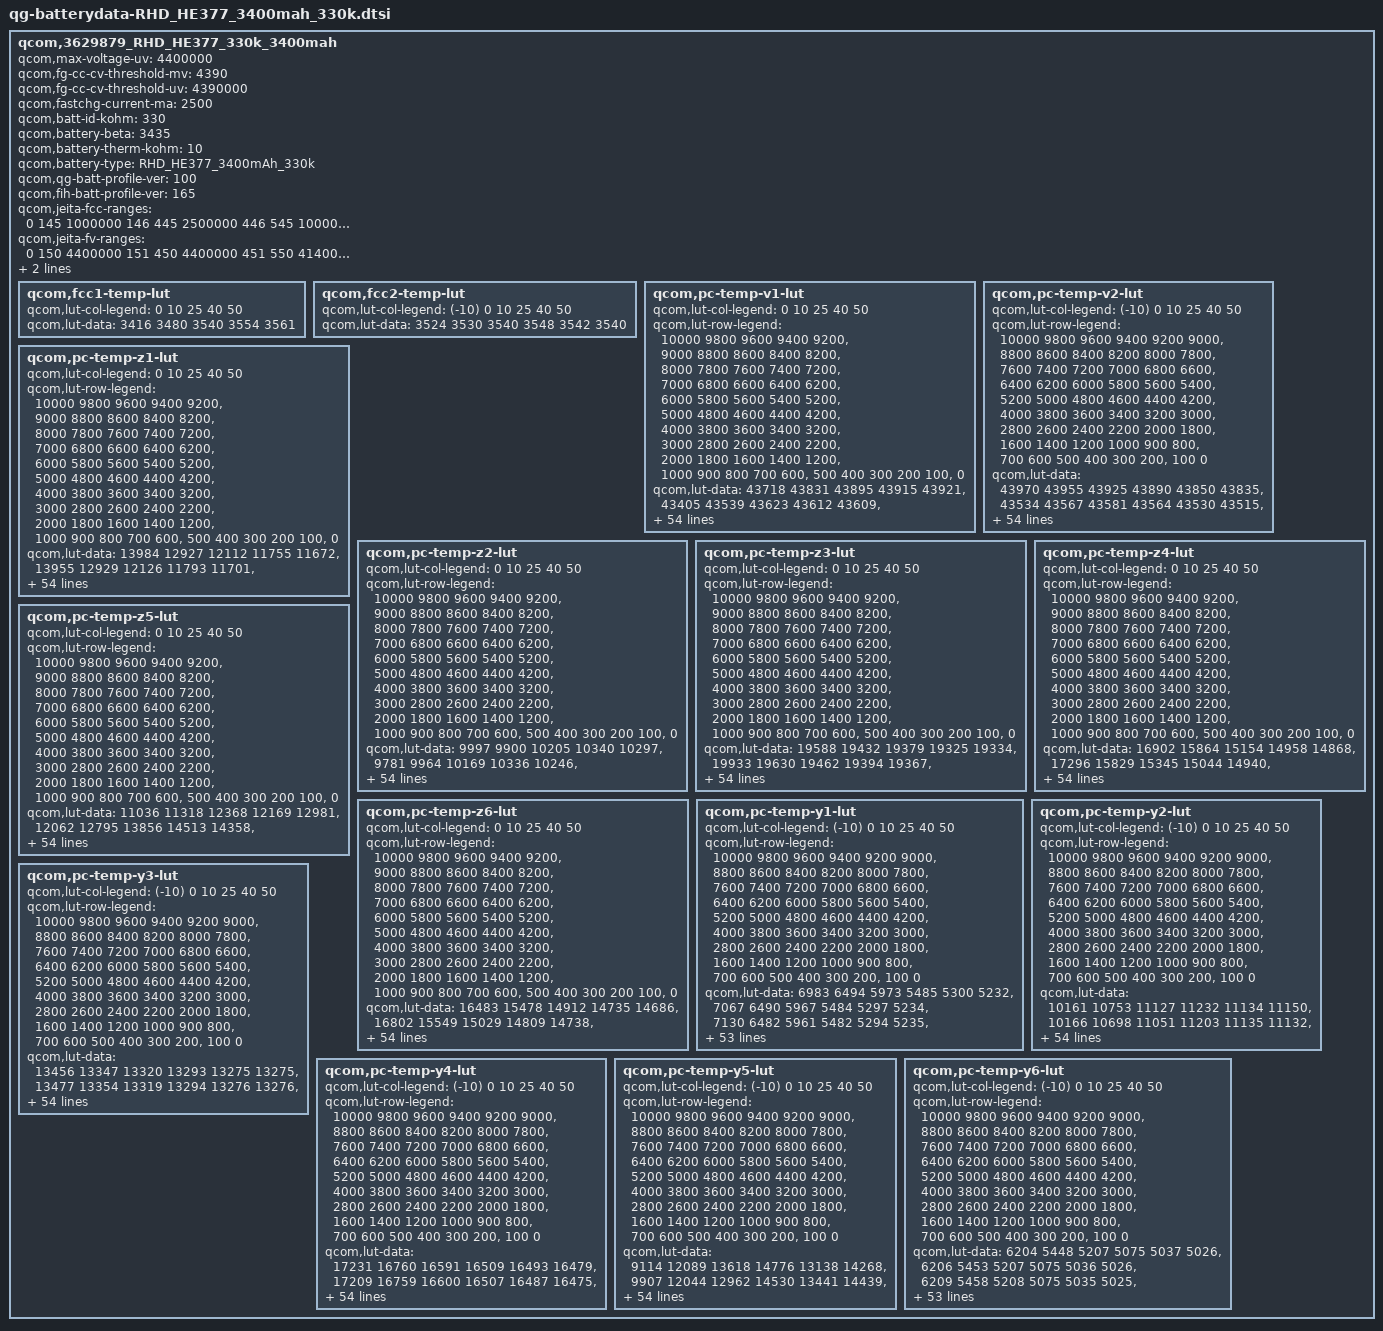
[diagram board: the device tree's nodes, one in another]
qcom,3629879_RHD_HE377_330k_3400mah {
	/* 3629879_FIH_HE377_3500mAh_averaged_MasterSlave_Oct1st2018 */
	qcom,max-voltage-uv = <4400000>;
	qcom,fg-cc-cv-threshold-mv = <4390>; // not use
	qcom,fg-cc-cv-threshold-uv = <4390000>; // not use
	qcom,fastchg-current-ma = <2500>;
	qcom,batt-id-kohm = <330>;
	qcom,battery-beta = <3435>;
	qcom,battery-therm-kohm = <10>;
	qcom,battery-type =
		"RHD_HE377_3400mAh_330k";
	qcom,qg-batt-profile-ver = <100>;
	qcom,fih-batt-profile-ver = <165>;

	qcom,jeita-fcc-ranges = <0   145   1000000
				 146 445  2500000
				 446 545  1000000
				 546 550  100000>;
	qcom,jeita-fv-ranges =  <0   150  4400000
				 151 450  4400000
				 451 550  4140000>;

	qcom,jeita-soft-thresholds = <0x257d 0xfb3>;
	qcom,jeita-hard-thresholds = <0x3733 0xbc2>;

	qcom,fcc1-temp-lut {
		qcom,lut-col-legend = <0 10 25 40 50>;
		qcom,lut-data = <3416 3480 3540 3554 3561>;
	};

	qcom,fcc2-temp-lut {
		qcom,lut-col-legend = <(-10) 0 10 25 40 50>;
		qcom,lut-data = <3524 3530 3540 3548 3542 3540>;
	};

	qcom,pc-temp-v1-lut {
		qcom,lut-col-legend = <0 10 25 40 50>;
		qcom,lut-row-legend = <10000 9800 9600 9400 9200>,
			<9000 8800 8600 8400 8200>,
			<8000 7800 7600 7400 7200>,
			<7000 6800 6600 6400 6200>,
			<6000 5800 5600 5400 5200>,
			<5000 4800 4600 4400 4200>,
			<4000 3800 3600 3400 3200>,
			<3000 2800 2600 2400 2200>,
			<2000 1800 1600 1400 1200>,
			<1000 900 800 700 600>,
			<500 400 300 200 100>,
			<0>;
		qcom,lut-data = <43718 43831 43895 43915 43921>,
			<43405 43539 43623 43612 43609>,
			<43133 43265 43357 43352 43348>,
			<42888 43011 43100 43108 43104>,
			<42653 42772 42854 42866 42865>,
			<42424 42539 42617 42630 42633>,
			<42202 42309 42382 42396 42403>,
			<41985 42084 42149 42163 42170>,
			<41773 41866 41921 41934 41940>,
			<41569 41653 41698 41708 41714>,
			<41387 41451 41481 41486 41491>,
			<41210 41270 41279 41269 41273>,
			<41001 41085 41095 41057 41056>,
			<40741 40857 40894 40848 40847>,
			<40474 40590 40639 40627 40643>,
			<40222 40338 40374 40408 40446>,
			<39980 40100 40169 40219 40257>,
			<39811 39895 40001 40055 40076>,
			<39706 39766 39849 39898 39903>,
			<39614 39677 39716 39747 39747>,
			<39504 39573 39586 39595 39596>,
			<39387 39434 39429 39414 39417>,
			<39262 39274 39250 39194 39197>,
			<39129 39083 39061 38991 38992>,
			<38993 38852 38842 38820 38825>,
			<38864 38673 38646 38670 38679>,
			<38737 38555 38535 38552 38556>,
			<38623 38464 38459 38453 38451>,
			<38522 38395 38386 38363 38356>,
			<38432 38340 38311 38278 38266>,
			<38365 38291 38243 38202 38186>,
			<38313 38243 38182 38134 38113>,
			<38269 38200 38129 38074 38048>,
			<38234 38162 38082 38020 37990>,
			<38205 38130 38043 37976 37940>,
			<38176 38098 38007 37934 37892>,
			<38152 38072 37971 37887 37838>,
			<38123 38043 37934 37837 37781>,
			<38079 37998 37885 37777 37715>,
			<38014 37926 37810 37704 37637>,
			<37933 37837 37718 37618 37547>,
			<37817 37728 37613 37511 37442>,
			<37681 37598 37487 37383 37318>,
			<37525 37440 37331 37227 37163>,
			<37373 37285 37181 37080 37015>,
			<37255 37171 37074 36980 36917>,
			<37218 37147 37044 36953 36892>,
			<37189 37121 37029 36936 36874>,
			<37164 37100 37012 36919 36859>,
			<37136 37075 36985 36889 36825>,
			<37029 36954 36830 36712 36623>,
			<36637 36558 36427 36307 36208>,
			<36082 36002 35870 35753 35647>,
			<35327 35242 35106 34993 34879>,
			<34141 34059 33921 33826 33685>,
			<30000 30000 30000 30000 30000>;
	};

	qcom,pc-temp-v2-lut {
		qcom,lut-col-legend = <(-10) 0 10 25 40 50>;
		qcom,lut-row-legend = <10000 9800 9600 9400 9200 9000>,
			<8800 8600 8400 8200 8000 7800>,
			<7600 7400 7200 7000 6800 6600>,
			<6400 6200 6000 5800 5600 5400>,
			<5200 5000 4800 4600 4400 4200>,
			<4000 3800 3600 3400 3200 3000>,
			<2800 2600 2400 2200 2000 1800>,
			<1600 1400 1200 1000 900 800>,
			<700 600 500 400 300 200>,
			<100 0>;
		qcom,lut-data = <43970 43955 43925 43890 43850 43835>,
			<43534 43567 43581 43564 43530 43515>,
			<43155 43222 43269 43264 43235 43219>,
			<42841 42928 42993 42994 42968 42953>,
			<42580 42678 42748 42751 42727 42714>,
			<42336 42440 42512 42515 42492 42481>,
			<42103 42207 42279 42280 42258 42247>,
			<41875 41981 42051 42048 42027 42016>,
			<41620 41760 41827 41821 41799 41788>,
			<41331 41541 41608 41597 41573 41562>,
			<41114 41336 41392 41376 41351 41340>,
			<41008 41159 41180 41154 41133 41122>,
			<40912 40982 40972 40937 40919 40908>,
			<40671 40765 40772 40741 40719 40703>,
			<40173 40508 40578 40558 40527 40503>,
			<39774 40231 40360 40355 40334 40310>,
			<39556 39905 40073 40095 40133 40121>,
			<39384 39602 39793 39853 39940 39939>,
			<39224 39423 39610 39704 39771 39771>,
			<39081 39302 39473 39596 39619 39614>,
			<38936 39170 39318 39453 39451 39443>,
			<38776 39007 39124 39230 39253 39249>,
			<38621 38842 38931 38999 39051 39051>,
			<38487 38698 38773 38815 38855 38855>,
			<38365 38565 38632 38652 38663 38662>,
			<38263 38446 38507 38517 38514 38512>,
			<38178 38340 38396 38406 38401 38398>,
			<38107 38242 38295 38307 38304 38300>,
			<38047 38148 38204 38216 38213 38207>,
			<37995 38058 38119 38133 38130 38120>,
			<37948 37985 38043 38057 38055 38043>,
			<37904 37923 37971 37986 37984 37973>,
			<37861 37872 37908 37920 37920 37909>,
			<37815 37831 37852 37858 37864 37853>,
			<37768 37798 37804 37801 37811 37800>,
			<37718 37762 37759 37745 37742 37725>,
			<37663 37725 37719 37691 37650 37610>,
			<37604 37683 37676 37633 37556 37495>,
			<37536 37632 37625 37565 37474 37406>,
			<37463 37571 37566 37490 37395 37326>,
			<37386 37498 37492 37410 37315 37243>,
			<37304 37407 37397 37320 37232 37160>,
			<37221 37291 37284 37211 37129 37056>,
			<37138 37143 37150 37076 36998 36924>,
			<37052 37030 37001 36927 36846 36782>,
			<36948 36941 36932 36885 36807 36749>,
			<36890 36902 36909 36871 36797 36737>,
			<36821 36859 36893 36852 36782 36724>,
			<36739 36807 36860 36825 36754 36693>,
			<36633 36714 36802 36745 36686 36614>,
			<36460 36534 36606 36487 36437 36324>,
			<36120 36148 36139 35982 35960 35829>,
			<35575 35548 35493 35320 35320 35174>,
			<34736 34690 34571 34372 34424 34254>,
			<33293 33297 33226 33050 33070 32859>,
			<28690 29213 28805 28338 29177 28649>;
	};

	qcom,pc-temp-z1-lut {
		qcom,lut-col-legend = <0 10 25 40 50>;
		qcom,lut-row-legend = <10000 9800 9600 9400 9200>,
			<9000 8800 8600 8400 8200>,
			<8000 7800 7600 7400 7200>,
			<7000 6800 6600 6400 6200>,
			<6000 5800 5600 5400 5200>,
			<5000 4800 4600 4400 4200>,
			<4000 3800 3600 3400 3200>,
			<3000 2800 2600 2400 2200>,
			<2000 1800 1600 1400 1200>,
			<1000 900 800 700 600>,
			<500 400 300 200 100>,
			<0>;
		qcom,lut-data = <13984 12927 12112 11755 11672>,
			<13955 12929 12126 11793 11701>,
			<13960 12928 12120 11790 11699>,
			<13967 12922 12114 11786 11697>,
			<13970 12913 12109 11783 11696>,
			<13963 12908 12103 11781 11695>,
			<13951 12910 12099 11779 11695>,
			<13941 12912 12095 11777 11694>,
			<13922 12907 12093 11776 11693>,
			<13908 12894 12092 11775 11692>,
			<13913 12888 12092 11774 11692>,
			<13924 12887 12092 11774 11691>,
			<13920 12888 12095 11778 11691>,
			<13879 12887 12096 11780 11691>,
			<13835 12885 12085 11775 11691>,
			<13803 12880 12069 11765 11690>,
			<13769 12857 12067 11763 11689>,
			<13759 12833 12069 11767 11691>,
			<13773 12835 12072 11771 11692>,
			<13787 12850 12078 11773 11693>,
			<13790 12864 12086 11775 11694>,
			<13796 12874 12091 11776 11695>,
			<13803 12883 12095 11777 11696>,
			<13813 12888 12098 11779 11698>,
			<13823 12891 12103 11782 11700>,
			<13834 12896 12109 11786 11703>,
			<13846 12909 12115 11790 11706>,
			<13853 12923 12121 11793 11709>,
			<13853 12926 12127 11797 11712>,
			<13851 12926 12132 11800 11715>,
			<13852 12927 12137 11804 11717>,
			<13855 12941 12142 11807 11720>,
			<13859 12959 12146 11811 11722>,
			<13872 12964 12151 11814 11724>,
			<13894 12964 12156 11817 11726>,
			<13908 12966 12161 11819 11729>,
			<13925 12971 12167 11822 11731>,
			<13939 12978 12173 11826 11733>,
			<13936 12986 12178 11829 11735>,
			<13923 12997 12183 11832 11737>,
			<13917 13005 12188 11836 11739>,
			<13915 13007 12192 11838 11742>,
			<13913 13011 12197 11840 11744>,
			<13911 13028 12202 11843 11746>,
			<13910 13040 12207 11846 11747>,
			<13912 13018 12208 11847 11748>,
			<13904 13015 12211 11848 11749>,
			<13889 13016 12208 11848 11749>,
			<13927 13023 12210 11851 11750>,
			<13931 13023 12212 11852 11753>,
			<13897 13027 12220 11857 11756>,
			<13930 13040 12231 11864 11763>,
			<13917 13065 12251 11875 11770>,
			<13938 13117 12269 11889 11783>,
			<13938 13117 12269 11889 11783>,
			<13938 13117 12269 11889 11783>;
	};

	qcom,pc-temp-z2-lut {
		qcom,lut-col-legend = <0 10 25 40 50>;
		qcom,lut-row-legend = <10000 9800 9600 9400 9200>,
			<9000 8800 8600 8400 8200>,
			<8000 7800 7600 7400 7200>,
			<7000 6800 6600 6400 6200>,
			<6000 5800 5600 5400 5200>,
			<5000 4800 4600 4400 4200>,
			<4000 3800 3600 3400 3200>,
			<3000 2800 2600 2400 2200>,
			<2000 1800 1600 1400 1200>,
			<1000 900 800 700 600>,
			<500 400 300 200 100>,
			<0>;
		qcom,lut-data = <9997 9900 10205 10340 10297>,
			<9781 9964 10169 10336 10246>,
			<9791 9999 10241 10402 10360>,
			<9834 9994 10294 10459 10483>,
			<9853 9974 10277 10448 10480>,
			<9851 9960 10244 10411 10420>,
			<9847 9952 10238 10398 10390>,
			<9840 9947 10246 10414 10394>,
			<9830 9941 10257 10429 10398>,
			<9819 9935 10267 10427 10380>,
			<9810 9933 10279 10421 10344>,
			<9802 9942 10288 10422 10333>,
			<9792 9957 10300 10434 10298>,
			<9774 9973 10308 10444 10263>,
			<9763 9993 10315 10445 10277>,
			<9768 10011 10320 10444 10310>,
			<9784 10026 10322 10430 10332>,
			<9797 10041 10325 10359 10342>,
			<9810 10070 10330 10311 10353>,
			<9820 10115 10361 10326 10372>,
			<9821 10143 10397 10366 10403>,
			<9819 10152 10400 10444 10477>,
			<9820 10159 10398 10630 10684>,
			<9828 10170 10394 10733 10814>,
			<9840 10185 10370 10586 10713>,
			<9856 10190 10345 10383 10542>,
			<9878 10187 10353 10383 10483>,
			<9898 10181 10384 10497 10464>,
			<9914 10175 10396 10553 10446>,
			<9928 10169 10389 10507 10388>,
			<9941 10166 10378 10445 10317>,
			<9953 10170 10365 10422 10284>,
			<9964 10176 10350 10407 10260>,
			<9974 10183 10346 10400 10252>,
			<9984 10193 10352 10400 10287>,
			<9997 10204 10363 10405 10343>,
			<10017 10217 10378 10449 10392>,
			<10040 10232 10399 10546 10440>,
			<10068 10242 10420 10576 10477>,
			<10100 10249 10444 10544 10504>,
			<10129 10256 10460 10514 10525>,
			<10154 10263 10460 10545 10541>,
			<10171 10270 10458 10595 10552>,
			<10142 10289 10471 10565 10536>,
			<10044 10420 10509 10544 10528>,
			<9993 10507 10540 10526 10506>,
			<9989 10746 10525 10556 10537>,
			<9963 10850 10533 10563 10547>,
			<9916 10934 10559 10547 10565>,
			<9938 11040 10576 10577 10705>,
			<9672 11013 10655 10634 10519>,
			<9723 10748 10712 10500 10298>,
			<9727 10567 10722 10447 10225>,
			<9587 10375 10643 10344 10140>,
			<9587 10375 10643 10344 10140>,
			<9587 10375 10643 10344 10140>;
	};

	qcom,pc-temp-z3-lut {
		qcom,lut-col-legend = <0 10 25 40 50>;
		qcom,lut-row-legend = <10000 9800 9600 9400 9200>,
			<9000 8800 8600 8400 8200>,
			<8000 7800 7600 7400 7200>,
			<7000 6800 6600 6400 6200>,
			<6000 5800 5600 5400 5200>,
			<5000 4800 4600 4400 4200>,
			<4000 3800 3600 3400 3200>,
			<3000 2800 2600 2400 2200>,
			<2000 1800 1600 1400 1200>,
			<1000 900 800 700 600>,
			<500 400 300 200 100>,
			<0>;
		qcom,lut-data = <19588 19432 19379 19325 19334>,
			<19933 19630 19462 19394 19367>,
			<19991 19751 19515 19427 19403>,
			<20000 19766 19538 19446 19427>,
			<20003 19770 19538 19453 19431>,
			<19988 19771 19535 19458 19432>,
			<19967 19765 19532 19458 19432>,
			<19964 19758 19526 19450 19428>,
			<19966 19751 19517 19440 19420>,
			<19968 19737 19504 19428 19411>,
			<19962 19722 19491 19415 19401>,
			<19951 19700 19486 19410 19394>,
			<19948 19681 19483 19408 19388>,
			<19955 19676 19482 19407 19382>,
			<19960 19673 19482 19406 19374>,
			<19944 19669 19482 19405 19365>,
			<19899 19657 19479 19401 19360>,
			<19852 19638 19465 19382 19357>,
			<19792 19613 19453 19366 19353>,
			<19748 19581 19444 19362 19346>,
			<19750 19568 19438 19360 19337>,
			<19768 19580 19443 19365 19339>,
			<19791 19600 19460 19393 19363>,
			<19831 19625 19468 19409 19380>,
			<19873 19657 19467 19387 19362>,
			<19891 19671 19464 19357 19333>,
			<19901 19669 19458 19357 19335>,
			<19905 19664 19448 19375 19366>,
			<19904 19658 19445 19391 19386>,
			<19899 19648 19459 19400 19388>,
			<19893 19640 19474 19407 19387>,
			<19880 19636 19477 19406 19384>,
			<19865 19632 19478 19402 19378>,
			<19849 19628 19477 19396 19371>,
			<19830 19623 19472 19389 19365>,
			<19809 19617 19467 19383 19359>,
			<19785 19612 19463 19381 19355>,
			<19761 19606 19460 19380 19351>,
			<19742 19601 19457 19377 19350>,
			<19725 19597 19453 19371 19349>,
			<19707 19592 19448 19366 19349>,
			<19687 19581 19442 19366 19346>,
			<19659 19569 19435 19367 19342>,
			<19553 19557 19432 19366 19345>,
			<19401 19515 19423 19361 19346>,
			<19344 19491 19413 19355 19345>,
			<19336 19349 19411 19349 19337>,
			<19330 19337 19387 19345 19332>,
			<19327 19323 19371 19344 19326>,
			<19317 19317 19376 19338 19312>,
			<19274 19325 19363 19341 19338>,
			<19307 19329 19356 19354 19356>,
			<19345 19329 19348 19352 19357>,
			<19356 19322 19349 19360 19362>,
			<19356 19322 19349 19360 19362>,
			<19356 19322 19349 19360 19362>;
	};

	qcom,pc-temp-z4-lut {
		qcom,lut-col-legend = <0 10 25 40 50>;
		qcom,lut-row-legend = <10000 9800 9600 9400 9200>,
			<9000 8800 8600 8400 8200>,
			<8000 7800 7600 7400 7200>,
			<7000 6800 6600 6400 6200>,
			<6000 5800 5600 5400 5200>,
			<5000 4800 4600 4400 4200>,
			<4000 3800 3600 3400 3200>,
			<3000 2800 2600 2400 2200>,
			<2000 1800 1600 1400 1200>,
			<1000 900 800 700 600>,
			<500 400 300 200 100>,
			<0>;
		qcom,lut-data = <16902 15864 15154 14958 14868>,
			<17296 15829 15345 15044 14940>,
			<17234 15755 15232 15004 14920>,
			<16820 15624 15107 14945 14886>,
			<16431 15414 15032 14900 14854>,
			<16181 15259 14971 14859 14821>,
			<15970 15163 14919 14830 14796>,
			<15804 15091 14871 14806 14780>,
			<15669 15039 14843 14790 14768>,
			<15558 15000 14835 14784 14762>,
			<15462 14967 14829 14780 14758>,
			<15381 14932 14821 14775 14754>,
			<15332 14908 14809 14770 14749>,
			<15302 14904 14800 14763 14742>,
			<15275 14902 14796 14755 14737>,
			<15240 14900 14793 14745 14732>,
			<15203 14886 14783 14737 14725>,
			<15174 14867 14760 14730 14716>,
			<15155 14851 14744 14724 14708>,
			<15136 14837 14737 14717 14705>,
			<15102 14822 14734 14712 14702>,
			<15053 14803 14735 14716 14706>,
			<15004 14788 14743 14748 14741>,
			<14948 14804 14757 14787 14785>,
			<14904 14866 14829 14845 14835>,
			<14898 14901 14904 14898 14879>,
			<14899 14905 14905 14895 14875>,
			<14902 14906 14883 14853 14820>,
			<14910 14900 14857 14812 14774>,
			<14921 14880 14823 14781 14753>,
			<14923 14861 14791 14755 14737>,
			<14917 14844 14770 14740 14726>,
			<14911 14829 14755 14729 14718>,
			<14904 14816 14745 14722 14713>,
			<14896 14805 14739 14718 14709>,
			<14889 14794 14735 14715 14708>,
			<14884 14781 14731 14717 14712>,
			<14878 14770 14729 14725 14725>,
			<14868 14764 14729 14732 14733>,
			<14855 14761 14735 14740 14737>,
			<14851 14758 14741 14745 14740>,
			<14858 14755 14735 14737 14735>,
			<14869 14753 14724 14724 14727>,
			<14962 14749 14721 14724 14726>,
			<15018 14740 14710 14719 14717>,
			<15037 14728 14690 14701 14696>,
			<15042 14878 14681 14693 14691>,
			<15041 14884 14691 14677 14674>,
			<15035 14893 14696 14654 14653>,
			<15034 14893 14686 14653 14655>,
			<15068 14882 14716 14682 14666>,
			<15066 14898 14739 14682 14662>,
			<15049 14905 14752 14686 14663>,
			<15058 14923 14757 14681 14660>,
			<15058 14923 14757 14681 14660>,
			<15058 14923 14757 14681 14660>;
	};

	qcom,pc-temp-z5-lut {
		qcom,lut-col-legend = <0 10 25 40 50>;
		qcom,lut-row-legend = <10000 9800 9600 9400 9200>,
			<9000 8800 8600 8400 8200>,
			<8000 7800 7600 7400 7200>,
			<7000 6800 6600 6400 6200>,
			<6000 5800 5600 5400 5200>,
			<5000 4800 4600 4400 4200>,
			<4000 3800 3600 3400 3200>,
			<3000 2800 2600 2400 2200>,
			<2000 1800 1600 1400 1200>,
			<1000 900 800 700 600>,
			<500 400 300 200 100>,
			<0>;
		qcom,lut-data = <11036 11318 12368 12169 12981>,
			<12062 12795 13856 14513 14358>,
			<12514 13842 15063 15717 16276>,
			<12754 14336 15728 16556 17796>,
			<12963 14637 15933 17219 18394>,
			<13176 14923 16071 17740 18701>,
			<13381 15312 16365 17971 19009>,
			<13615 15655 17059 18267 19458>,
			<13885 15843 17480 18492 19787>,
			<14124 16053 17268 18152 19525>,
			<14284 16176 16939 17456 18815>,
			<14421 16364 16938 17273 18499>,
			<14618 16636 17254 17470 18417>,
			<14959 16934 17597 17791 18275>,
			<15192 17287 17940 18494 17913>,
			<15053 17425 18273 19400 17442>,
			<14643 17356 18433 19398 17368>,
			<14225 17220 18514 18112 17820>,
			<13714 16959 18641 17218 18179>,
			<13340 16488 19009 17367 17882>,
			<13453 16314 19698 17827 17314>,
			<14045 17935 21672 20166 18201>,
			<14963 21130 26082 29023 24603>,
			<17321 26314 28028 34179 28979>,
			<20622 35011 26733 27018 23761>,
			<23732 38970 24539 17084 15569>,
			<27085 36279 22135 15699 14314>,
			<29261 32040 19282 15966 15510>,
			<30310 29196 18333 16367 16844>,
			<31010 26737 19489 17657 18001>,
			<30948 25576 21294 19455 19163>,
			<29741 25339 23185 20984 20188>,
			<28202 25223 25410 22506 21125>,
			<26715 25233 26809 23634 22042>,
			<25028 25322 27752 24405 23182>,
			<23409 25417 28500 25006 24007>,
			<21693 25484 29071 25539 23842>,
			<20372 25561 29531 25996 23061>,
			<19819 25806 29544 25903 22212>,
			<19485 26496 28413 23173 21177>,
			<19001 26879 26875 20719 20108>,
			<18120 24919 25266 20790 19147>,
			<17224 22628 23963 21037 18458>,
			<15098 21794 23728 20543 18502>,
			<12790 20781 23562 19954 19101>,
			<11841 20335 23951 19829 19732>,
			<11715 12435 23698 19038 18044>,
			<11645 12175 18500 19253 18513>,
			<11618 11952 16341 21151 19608>,
			<11567 11886 17196 20632 17626>,
			<11288 12101 15582 17191 18639>,
			<11449 12016 14373 16954 19739>,
			<11568 11932 13665 16120 18876>,
			<11522 11715 13453 16527 18917>,
			<11522 11715 13453 16527 18917>,
			<11522 11715 13453 16527 18917>;
	};

	qcom,pc-temp-z6-lut {
		qcom,lut-col-legend = <0 10 25 40 50>;
		qcom,lut-row-legend = <10000 9800 9600 9400 9200>,
			<9000 8800 8600 8400 8200>,
			<8000 7800 7600 7400 7200>,
			<7000 6800 6600 6400 6200>,
			<6000 5800 5600 5400 5200>,
			<5000 4800 4600 4400 4200>,
			<4000 3800 3600 3400 3200>,
			<3000 2800 2600 2400 2200>,
			<2000 1800 1600 1400 1200>,
			<1000 900 800 700 600>,
			<500 400 300 200 100>,
			<0>;
		qcom,lut-data = <16483 15478 14912 14735 14686>,
			<16802 15549 15029 14809 14738>,
			<16793 15573 15005 14804 14743>,
			<16608 15541 14974 14795 14744>,
			<16428 15440 14945 14784 14741>,
			<16302 15361 14914 14768 14726>,
			<16193 15314 14888 14753 14713>,
			<16113 15277 14864 14739 14702>,
			<16051 15246 14846 14726 14693>,
			<15999 15220 14835 14716 14686>,
			<15951 15196 14826 14707 14679>,
			<15909 15170 14819 14702 14672>,
			<15877 15149 14813 14699 14666>,
			<15855 15139 14808 14696 14660>,
			<15832 15133 14804 14692 14653>,
			<15794 15125 14800 14685 14646>,
			<15746 15110 14791 14677 14640>,
			<15707 15091 14775 14665 14634>,
			<15671 15071 14763 14655 14629>,
			<15647 15051 14756 14650 14623>,
			<15641 15042 14752 14646 14617>,
			<15638 15045 14755 14651 14621>,
			<15637 15050 14766 14680 14650>,
			<15641 15068 14781 14705 14677>,
			<15648 15114 14814 14718 14687>,
			<15656 15140 14844 14727 14694>,
			<15667 15142 14842 14726 14694>,
			<15675 15143 14829 14719 14687>,
			<15682 15139 14818 14711 14680>,
			<15686 15128 14811 14704 14673>,
			<15686 15118 14806 14696 14665>,
			<15680 15111 14800 14689 14658>,
			<15673 15105 14795 14683 14651>,
			<15665 15099 14790 14677 14646>,
			<15657 15093 14785 14670 14640>,
			<15648 15088 14781 14666 14636>,
			<15639 15082 14779 14667 14637>,
			<15630 15077 14777 14670 14639>,
			<15623 15076 14777 14671 14642>,
			<15616 15076 14778 14671 14643>,
			<15609 15076 14779 14671 14644>,
			<15603 15072 14775 14668 14641>,
			<15595 15067 14767 14663 14636>,
			<15584 15063 14765 14663 14637>,
			<15532 15042 14757 14659 14634>,
			<15509 15028 14744 14647 14624>,
			<15510 15021 14740 14642 14618>,
			<15506 15019 14731 14632 14608>,
			<15502 15016 14726 14622 14596>,
			<15499 15014 14725 14619 14589>,
			<15505 15019 14733 14633 14609>,
			<15530 15034 14742 14642 14618>,
			<15557 15050 14749 14646 14622>,
			<15592 15070 14757 14651 14626>,
			<15592 15070 14757 14651 14626>,
			<15592 15070 14757 14651 14626>;
	};

	qcom,pc-temp-y1-lut {
		qcom,lut-col-legend = <(-10) 0 10 25 40 50>;
		qcom,lut-row-legend = <10000 9800 9600 9400 9200 9000>,
			<8800 8600 8400 8200 8000 7800>,
			<7600 7400 7200 7000 6800 6600>,
			<6400 6200 6000 5800 5600 5400>,
			<5200 5000 4800 4600 4400 4200>,
			<4000 3800 3600 3400 3200 3000>,
			<2800 2600 2400 2200 2000 1800>,
			<1600 1400 1200 1000 900 800>,
			<700 600 500 400 300 200>,
			<100 0>;
		qcom,lut-data = <6983 6494 5973 5485 5300 5232>,
			<7067 6490 5967 5484 5297 5234>,
			<7130 6482 5961 5482 5294 5235>,
			<7171 6473 5955 5481 5291 5236>,
			<7194 6465 5950 5479 5289 5236>,
			<7200 6461 5944 5477 5287 5236>,
			<7176 6459 5939 5474 5286 5236>,
			<7143 6458 5934 5472 5285 5235>,
			<7135 6455 5932 5470 5285 5234>,
			<7133 6446 5931 5469 5284 5233>,
			<7131 6441 5930 5467 5283 5233>,
			<7136 6444 5926 5466 5282 5232>,
			<7144 6448 5921 5464 5281 5232>,
			<7146 6451 5918 5463 5280 5232>,
			<7151 6452 5915 5462 5279 5233>,
			<7154 6454 5914 5462 5279 5233>,
			<7153 6457 5920 5466 5280 5233>,
			<7150 6461 5927 5470 5281 5233>,
			<7146 6459 5928 5472 5282 5233>,
			<7134 6451 5927 5472 5282 5235>,
			<7128 6448 5927 5472 5283 5235>,
			<7126 6451 5927 5472 5284 5236>,
			<7124 6457 5927 5473 5285 5237>,
			<7137 6462 5927 5475 5286 5237>,
			<7180 6469 5928 5478 5287 5237>,
			<7198 6471 5929 5481 5288 5237>,
			<7171 6461 5931 5483 5290 5238>,
			<7139 6451 5934 5486 5292 5241>,
			<7128 6453 5941 5490 5294 5242>,
			<7116 6461 5951 5494 5296 5244>,
			<7110 6464 5955 5497 5298 5245>,
			<7106 6459 5951 5500 5301 5247>,
			<7104 6454 5948 5503 5304 5249>,
			<7110 6456 5952 5507 5306 5251>,
			<7125 6463 5956 5511 5309 5253>,
			<7129 6465 5958 5514 5311 5255>,
			<7117 6461 5955 5516 5314 5258>,
			<7105 6456 5953 5517 5315 5259>,
			<7101 6459 5953 5518 5315 5260>,
			<7099 6465 5953 5518 5316 5260>,
			<7102 6467 5954 5520 5316 5260>,
			<7135 6463 5959 5524 5317 5260>,
			<7142 6462 5964 5524 5318 5261>,
			<7111 6465 5970 5524 5320 5263>,
			<7111 6488 5979 5525 5321 5265>,
			<7104 6492 5967 5528 5322 5265>,
			<7120 6472 5976 5528 5323 5265>,
			<7107 6482 5979 5529 5324 5266>,
			<7109 6476 5973 5530 5324 5265>,
			<7147 6489 5984 5530 5324 5266>,
			<7115 6477 5986 5536 5327 5269>,
			<7103 6504 5990 5542 5332 5273>,
			<7112 6502 6019 5554 5337 5278>,
			<7158 6502 6036 5573 5347 5286>,
			<7158 6502 6036 5573 5347 5286>,
			<7158 6502 6036 5573 5347 5286>;
	};

	qcom,pc-temp-y2-lut {
		qcom,lut-col-legend = <(-10) 0 10 25 40 50>;
		qcom,lut-row-legend = <10000 9800 9600 9400 9200 9000>,
			<8800 8600 8400 8200 8000 7800>,
			<7600 7400 7200 7000 6800 6600>,
			<6400 6200 6000 5800 5600 5400>,
			<5200 5000 4800 4600 4400 4200>,
			<4000 3800 3600 3400 3200 3000>,
			<2800 2600 2400 2200 2000 1800>,
			<1600 1400 1200 1000 900 800>,
			<700 600 500 400 300 200>,
			<100 0>;
		qcom,lut-data = <10161 10753 11127 11232 11134 11150>,
			<10166 10698 11051 11203 11135 11132>,
			<10175 10642 10977 11168 11129 11109>,
			<10188 10589 10906 11131 11117 11083>,
			<10204 10544 10844 11098 11101 11057>,
			<10222 10513 10792 11075 11082 11032>,
			<10249 10490 10749 11059 11054 11001>,
			<10275 10474 10712 11042 11025 10974>,
			<10276 10475 10686 11013 11008 10960>,
			<10262 10485 10666 10962 10996 10949>,
			<10255 10491 10651 10928 10986 10939>,
			<10355 10492 10637 10910 10975 10927>,
			<10488 10493 10628 10898 10963 10915>,
			<10501 10514 10634 10896 10939 10911>,
			<10481 10590 10662 10902 10895 10910>,
			<10470 10641 10692 10910 10879 10909>,
			<10487 10657 10724 10919 10938 10911>,
			<10511 10669 10756 10933 11024 10915>,
			<10461 10684 10778 10966 11076 10941>,
			<10238 10702 10796 11020 11117 11011>,
			<10115 10722 10818 11038 11158 11050>,
			<9935 10742 10850 11023 11211 11057>,
			<9730 10765 10887 11011 11247 11059>,
			<9700 10791 10925 11035 11229 11080>,
			<9686 10821 10964 11092 11179 11129>,
			<9679 10842 10994 11118 11163 11162>,
			<9675 10853 11019 11126 11186 11189>,
			<9672 10864 11037 11133 11211 11213>,
			<9669 10893 11048 11148 11217 11235>,
			<9667 10939 11056 11166 11218 11263>,
			<9665 10963 11057 11173 11219 11281>,
			<9663 10972 11052 11176 11241 11301>,
			<9661 10977 11047 11177 11261 11316>,
			<9660 10953 11044 11169 11275 11314>,
			<9659 10885 11040 11153 11296 11310>,
			<9658 10828 11033 11148 11293 11310>,
			<9657 10787 11018 11150 11261 11298>,
			<9656 10749 11001 11152 11240 11286>,
			<9655 10712 10986 11157 11239 11279>,
			<9654 10675 10967 11165 11239 11272>,
			<9653 10633 10945 11169 11235 11252>,
			<9653 10588 10915 11173 11216 11203>,
			<9652 10403 10884 11174 11206 11194>,
			<9652 9780 10856 11170 11200 11210>,
			<9652 9702 10842 11138 11218 11288>,
			<9652 9696 10819 11106 11166 11114>,
			<9652 9682 10770 11118 11155 11099>,
			<9652 9673 10697 11130 11113 10986>,
			<9651 9666 10667 11102 11111 10944>,
			<9651 9664 10629 11090 11099 10939>,
			<9651 9661 10582 11075 11029 10928>,
			<9651 9658 10496 11039 10989 10860>,
			<9651 9655 10399 10907 10936 10761>,
			<9651 9653 10287 10822 10793 10619>,
			<9651 9653 10287 10822 10793 10619>,
			<9651 9653 10287 10822 10793 10619>;
	};

	qcom,pc-temp-y3-lut {
		qcom,lut-col-legend = <(-10) 0 10 25 40 50>;
		qcom,lut-row-legend = <10000 9800 9600 9400 9200 9000>,
			<8800 8600 8400 8200 8000 7800>,
			<7600 7400 7200 7000 6800 6600>,
			<6400 6200 6000 5800 5600 5400>,
			<5200 5000 4800 4600 4400 4200>,
			<4000 3800 3600 3400 3200 3000>,
			<2800 2600 2400 2200 2000 1800>,
			<1600 1400 1200 1000 900 800>,
			<700 600 500 400 300 200>,
			<100 0>;
		qcom,lut-data = <13456 13347 13320 13293 13275 13275>,
			<13477 13354 13319 13294 13276 13276>,
			<13513 13364 13319 13294 13277 13276>,
			<13554 13374 13319 13294 13278 13277>,
			<13588 13385 13320 13295 13279 13277>,
			<13603 13394 13321 13295 13280 13278>,
			<13605 13402 13325 13296 13281 13279>,
			<13607 13411 13331 13296 13281 13279>,
			<13606 13419 13335 13296 13281 13280>,
			<13599 13426 13341 13296 13281 13280>,
			<13589 13433 13346 13296 13282 13281>,
			<13569 13442 13351 13295 13285 13280>,
			<13548 13448 13356 13295 13290 13280>,
			<13538 13448 13362 13298 13290 13282>,
			<13533 13446 13369 13306 13290 13285>,
			<13526 13442 13372 13311 13290 13287>,
			<13509 13428 13370 13311 13291 13286>,
			<13490 13412 13368 13311 13293 13285>,
			<13473 13407 13364 13312 13295 13286>,
			<13446 13404 13359 13315 13297 13289>,
			<13433 13401 13354 13316 13297 13291>,
			<13428 13393 13348 13312 13296 13290>,
			<13424 13384 13341 13308 13294 13287>,
			<13422 13376 13334 13303 13289 13283>,
			<13414 13367 13327 13297 13281 13277>,
			<13410 13364 13324 13295 13279 13275>,
			<13404 13364 13322 13296 13279 13276>,
			<13401 13364 13322 13296 13279 13276>,
			<13413 13358 13322 13297 13280 13275>,
			<13439 13345 13322 13297 13281 13275>,
			<13467 13339 13323 13297 13281 13275>,
			<13496 13338 13324 13297 13281 13275>,
			<13529 13338 13326 13297 13281 13276>,
			<13567 13342 13327 13298 13282 13277>,
			<13612 13353 13328 13298 13283 13278>,
			<13667 13362 13328 13298 13283 13278>,
			<13736 13369 13327 13298 13282 13276>,
			<13821 13375 13326 13298 13280 13275>,
			<13925 13381 13327 13298 13280 13275>,
			<14055 13387 13330 13297 13279 13275>,
			<14210 13392 13331 13296 13280 13276>,
			<14401 13398 13333 13296 13282 13276>,
			<14630 13399 13334 13296 13283 13277>,
			<14904 13392 13334 13296 13283 13277>,
			<15159 13416 13326 13294 13279 13275>,
			<15071 13422 13325 13298 13281 13279>,
			<15260 13454 13328 13298 13285 13281>,
			<15434 13489 13342 13298 13288 13286>,
			<15615 13552 13349 13304 13291 13288>,
			<15774 13613 13366 13306 13295 13291>,
			<15915 13711 13372 13304 13290 13286>,
			<16040 13804 13371 13302 13292 13285>,
			<16237 14046 13393 13312 13295 13290>,
			<16861 14550 13425 13320 13299 13294>,
			<16861 14550 13425 13320 13299 13294>,
			<16861 14550 13425 13320 13299 13294>;
	};

	qcom,pc-temp-y4-lut {
		qcom,lut-col-legend = <(-10) 0 10 25 40 50>;
		qcom,lut-row-legend = <10000 9800 9600 9400 9200 9000>,
			<8800 8600 8400 8200 8000 7800>,
			<7600 7400 7200 7000 6800 6600>,
			<6400 6200 6000 5800 5600 5400>,
			<5200 5000 4800 4600 4400 4200>,
			<4000 3800 3600 3400 3200 3000>,
			<2800 2600 2400 2200 2000 1800>,
			<1600 1400 1200 1000 900 800>,
			<700 600 500 400 300 200>,
			<100 0>;
		qcom,lut-data = <17231 16760 16591 16509 16493 16479>,
			<17209 16759 16600 16507 16487 16475>,
			<17201 16763 16611 16506 16484 16472>,
			<17205 16770 16621 16507 16482 16470>,
			<17217 16779 16629 16510 16482 16469>,
			<17234 16786 16634 16512 16481 16469>,
			<17274 16793 16636 16516 16483 16470>,
			<17316 16802 16637 16521 16487 16471>,
			<17317 16818 16641 16528 16491 16473>,
			<17291 16847 16651 16538 16498 16477>,
			<17280 16877 16663 16549 16502 16481>,
			<17593 16901 16675 16563 16503 16487>,
			<18012 16929 16692 16577 16504 16494>,
			<17936 16985 16724 16585 16510 16497>,
			<17396 17084 16780 16590 16525 16500>,
			<17081 17126 16804 16597 16540 16504>,
			<17045 16978 16807 16614 16550 16514>,
			<17026 16800 16808 16638 16561 16527>,
			<17038 16781 16803 16679 16580 16541>,
			<17105 16782 16781 16736 16605 16557>,
			<17140 16782 16750 16750 16614 16567>,
			<17120 16752 16679 16684 16612 16574>,
			<17087 16713 16612 16603 16608 16578>,
			<17056 16699 16591 16554 16577 16556>,
			<17016 16692 16579 16514 16509 16499>,
			<16996 16685 16573 16501 16484 16479>,
			<16996 16676 16569 16497 16482 16478>,
			<16999 16669 16568 16495 16482 16478>,
			<16998 16671 16568 16497 16484 16480>,
			<16996 16678 16568 16502 16492 16488>,
			<16998 16680 16568 16508 16500 16497>,
			<17002 16679 16567 16516 16511 16507>,
			<17008 16679 16565 16522 16523 16519>,
			<17016 16680 16564 16525 16538 16534>,
			<17025 16681 16563 16528 16553 16548>,
			<17031 16683 16565 16527 16550 16545>,
			<17037 16695 16575 16522 16511 16505>,
			<17041 16711 16584 16516 16482 16475>,
			<17043 16727 16586 16506 16479 16473>,
			<17044 16744 16588 16496 16478 16473>,
			<17047 16757 16589 16496 16480 16475>,
			<17054 16764 16589 16504 16488 16485>,
			<17065 16783 16592 16510 16494 16489>,
			<17088 16837 16597 16512 16496 16490>,
			<17119 16847 16594 16493 16471 16463>,
			<17094 16844 16586 16493 16480 16475>,
			<17124 16873 16601 16510 16494 16489>,
			<17169 16923 16619 16534 16512 16511>,
			<17231 16995 16662 16564 16540 16541>,
			<17290 17088 16733 16587 16558 16554>,
			<17329 17159 16767 16562 16510 16490>,
			<17324 17170 16722 16545 16493 16484>,
			<17296 17208 16764 16579 16503 16493>,
			<17442 17334 16853 16666 16552 16538>,
			<17442 17334 16853 16666 16552 16538>,
			<17442 17334 16853 16666 16552 16538>;
	};

	qcom,pc-temp-y5-lut {
		qcom,lut-col-legend = <(-10) 0 10 25 40 50>;
		qcom,lut-row-legend = <10000 9800 9600 9400 9200 9000>,
			<8800 8600 8400 8200 8000 7800>,
			<7600 7400 7200 7000 6800 6600>,
			<6400 6200 6000 5800 5600 5400>,
			<5200 5000 4800 4600 4400 4200>,
			<4000 3800 3600 3400 3200 3000>,
			<2800 2600 2400 2200 2000 1800>,
			<1600 1400 1200 1000 900 800>,
			<700 600 500 400 300 200>,
			<100 0>;
		qcom,lut-data = <9114 12089 13618 14776 13138 14268>,
			<9907 12044 12962 14530 13441 14439>,
			<10741 12084 12505 14292 13625 14553>,
			<11531 12180 12212 14064 13720 14614>,
			<12196 12305 12048 13849 13755 14631>,
			<12651 12429 11981 13650 13759 14610>,
			<12970 12587 12110 13481 13662 14541>,
			<13180 12772 12315 13309 13471 14429>,
			<13036 12938 12363 13078 13245 14280>,
			<12283 13131 12425 12778 12939 14047>,
			<11858 13244 12479 12482 12815 13783>,
			<12134 13294 12541 12146 13318 13408>,
			<12712 13392 12630 11897 13932 13097>,
			<13628 13844 12752 12028 13805 13236>,
			<15230 15079 12940 12517 13162 13810>,
			<15966 15780 13253 12766 12874 14056>,
			<15026 15912 14236 12798 13012 13576>,
			<13694 15983 15328 12828 13192 13041>,
			<13153 15992 15806 13014 13251 13049>,
			<12889 15991 16129 13536 13274 13258>,
			<12769 15927 16223 14308 13429 13571>,
			<12088 15559 16206 16063 15072 14321>,
			<11319 15021 16168 17443 16647 14971>,
			<11193 14488 15692 17000 16252 15013>,
			<11063 13910 14550 15892 15100 14954>,
			<10974 13717 14084 15593 14726 14939>,
			<10854 13875 14016 15912 14890 14989>,
			<10749 14039 13986 16196 15109 15031>,
			<10763 13725 14011 16308 15356 14802>,
			<10823 12858 14094 16440 15643 14293>,
			<10879 12470 14242 16474 15700 14143>,
			<10961 12380 14639 16463 15589 14226>,
			<11040 12332 15056 16503 15521 14380>,
			<11071 12570 15373 16758 15941 14875>,
			<11086 13258 15658 17117 16740 15660>,
			<11096 13795 15685 17283 17042 15990>,
			<11132 14234 15367 17406 17040 16118>,
			<11160 14598 15083 17464 16924 16193>,
			<11156 14842 15193 17324 16445 16139>,
			<11151 15026 15502 17035 15835 15945>,
			<11139 15104 15589 16688 15831 15671>,
			<11103 15112 15526 16266 16276 15081>,
			<11096 14515 15345 15966 16314 14776>,
			<11169 11746 14918 15691 15973 14635>,
			<11278 11424 13382 15765 15479 15667>,
			<11299 11258 13388 16548 14878 14838>,
			<11409 11370 13335 15683 15082 14410>,
			<11429 11380 14461 14844 14739 15031>,
			<11506 11588 14350 15139 14592 14359>,
			<11824 11651 15101 14612 14824 14748>,
			<12137 12144 15231 14698 15082 15148>,
			<11755 11819 14766 14983 17132 14990>,
			<11438 11599 15005 16572 17538 17042>,
			<10833 11360 14777 17034 17832 17669>,
			<10833 11360 14777 17034 17832 17669>,
			<10833 11360 14777 17034 17832 17669>;
	};

	qcom,pc-temp-y6-lut {
		qcom,lut-col-legend = <(-10) 0 10 25 40 50>;
		qcom,lut-row-legend = <10000 9800 9600 9400 9200 9000>,
			<8800 8600 8400 8200 8000 7800>,
			<7600 7400 7200 7000 6800 6600>,
			<6400 6200 6000 5800 5600 5400>,
			<5200 5000 4800 4600 4400 4200>,
			<4000 3800 3600 3400 3200 3000>,
			<2800 2600 2400 2200 2000 1800>,
			<1600 1400 1200 1000 900 800>,
			<700 600 500 400 300 200>,
			<100 0>;
		qcom,lut-data = <6204 5448 5207 5075 5037 5026>,
			<6206 5453 5207 5075 5036 5026>,
			<6209 5458 5208 5075 5035 5025>,
			<6212 5462 5209 5076 5035 5025>,
			<6214 5467 5211 5077 5036 5026>,
			<6217 5471 5213 5078 5037 5026>,
			<6220 5474 5215 5079 5038 5027>,
			<6223 5478 5217 5081 5039 5028>,
			<6217 5484 5221 5083 5040 5029>,
			<6188 5495 5226 5085 5042 5031>,
			<6173 5506 5232 5088 5044 5032>,
			<6242 5515 5238 5091 5046 5034>,
			<6335 5525 5245 5095 5049 5035>,
			<6312 5541 5257 5100 5053 5038>,
			<6167 5564 5277 5106 5056 5041>,
			<6080 5573 5285 5113 5060 5044>,
			<6066 5523 5284 5118 5064 5046>,
			<6059 5462 5283 5125 5069 5049>,
			<6059 5455 5279 5137 5076 5054>,
			<6065 5455 5269 5155 5084 5061>,
			<6067 5454 5256 5159 5087 5064>,
			<6058 5442 5232 5138 5086 5064>,
			<6048 5426 5209 5111 5082 5064>,
			<6049 5420 5198 5093 5069 5055>,
			<6053 5415 5190 5078 5044 5034>,
			<6060 5414 5188 5073 5035 5027>,
			<6079 5417 5188 5073 5035 5026>,
			<6107 5420 5187 5073 5035 5026>,
			<6137 5420 5188 5074 5036 5027>,
			<6172 5420 5190 5076 5039 5029>,
			<6209 5421 5193 5079 5043 5031>,
			<6249 5426 5195 5081 5046 5035>,
			<6293 5434 5198 5083 5049 5039>,
			<6341 5445 5200 5085 5054 5044>,
			<6392 5461 5203 5087 5059 5049>,
			<6451 5478 5206 5087 5059 5048>,
			<6518 5496 5209 5086 5047 5036>,
			<6595 5517 5213 5085 5038 5026>,
			<6684 5540 5217 5082 5037 5026>,
			<6788 5566 5221 5079 5036 5026>,
			<6909 5595 5225 5079 5037 5027>,
			<7058 5630 5229 5081 5041 5030>,
			<7233 5665 5234 5084 5044 5032>,
			<7441 5701 5239 5085 5045 5033>,
			<7637 5760 5237 5078 5035 5024>,
			<7572 5771 5237 5082 5039 5030>,
			<7716 5838 5247 5087 5046 5036>,
			<7853 5917 5266 5094 5053 5046>,
			<7999 6017 5289 5107 5064 5056>,
			<8128 6119 5329 5115 5072 5062>,
			<8246 6238 5352 5108 5055 5040>,
			<8340 6348 5352 5103 5052 5038>,
			<8481 6592 5409 5123 5058 5046>,
			<9023 7041 5502 5157 5076 5063>,
			<9023 7041 5502 5157 5076 5063>,
			<9023 7041 5502 5157 5076 5063>;
	};

};
